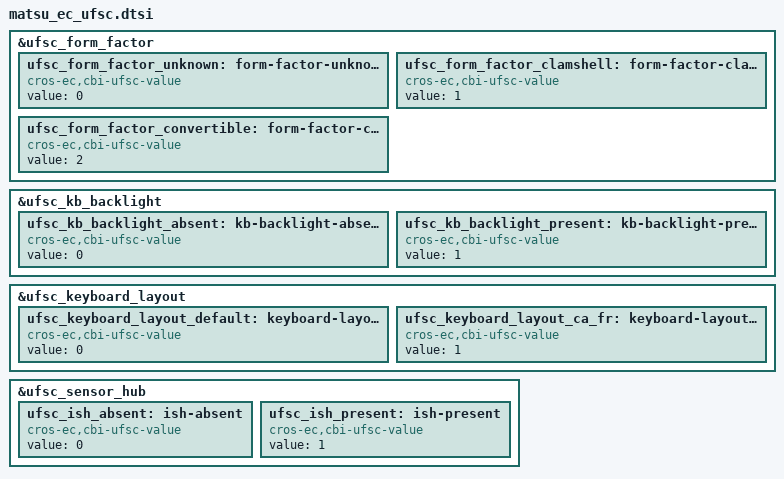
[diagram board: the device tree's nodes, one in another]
/* Auto-generated by generate_ufsc.py */

&ufsc_form_factor {
	ufsc_form_factor_unknown: form-factor-unknown {
		compatible = "cros-ec,cbi-ufsc-value";
		status = "okay";
		value = <0>;
	};
	ufsc_form_factor_clamshell: form-factor-clamshell {
		compatible = "cros-ec,cbi-ufsc-value";
		status = "okay";
		value = <1>;
	};
	ufsc_form_factor_convertible: form-factor-convertible {
		compatible = "cros-ec,cbi-ufsc-value";
		status = "okay";
		value = <2>;
	};
};

&ufsc_kb_backlight {
	ufsc_kb_backlight_absent: kb-backlight-absent {
		compatible = "cros-ec,cbi-ufsc-value";
		status = "okay";
		value = <0>;
	};
	ufsc_kb_backlight_present: kb-backlight-present {
		compatible = "cros-ec,cbi-ufsc-value";
		status = "okay";
		value = <1>;
	};
};

&ufsc_keyboard_layout {
	ufsc_keyboard_layout_default: keyboard-layout-default {
		compatible = "cros-ec,cbi-ufsc-value";
		status = "okay";
		value = <0>;
	};
	ufsc_keyboard_layout_ca_fr: keyboard-layout-ca-fr {
		compatible = "cros-ec,cbi-ufsc-value";
		status = "okay";
		value = <1>;
	};
};

&ufsc_sensor_hub {
	ufsc_ish_absent: ish-absent {
		compatible = "cros-ec,cbi-ufsc-value";
		status = "okay";
		value = <0>;
	};
	ufsc_ish_present: ish-present {
		compatible = "cros-ec,cbi-ufsc-value";
		status = "okay";
		value = <1>;
	};
};

